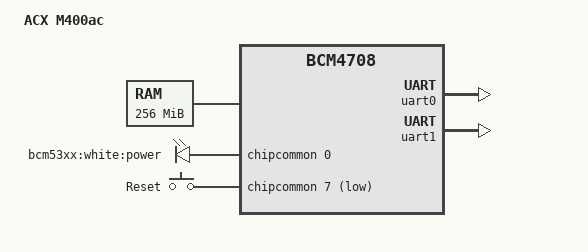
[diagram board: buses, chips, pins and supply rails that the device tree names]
/*
 * Broadcom BCM470X / BCM5301X arm platform code.
 * DTS for SmartRG SR400ac
 *
 * Copyright (C) 2015 Rafał Miłecki <zajec5@gmail.com>
 *
 * Licensed under the GNU/GPL. See COPYING for details.
 */

/dts-v1/;

#include "bcm4708.dtsi"

/ {
	compatible = "acx,m400ac", "brcm,bcm4708";
	model = "ACX M400ac";

	chosen {
		bootargs = "console=ttyS0,115200 earlyprintk";
	};

	memory {
		reg = <0x00000000 0x08000000 0x88000000 0x08000000>;
	};

	chipcommonA {
		uart0: serial@0300 {
			status = "okay";
		};

		uart1: serial@0400 {
			status = "okay";
		};
	};

	leds {
		compatible = "gpio-leds";

		power-white {
			label = "bcm53xx:white:power";
			gpios = <&chipcommon 0 GPIO_ACTIVE_HIGH>;
			linux,default-trigger = "default-on";
		};
	};

	gpio-keys {
		compatible = "gpio-keys";
		#address-cells = <1>;
		#size-cells = <0>;

		restart {
			label = "Reset";
			linux,code = <KEY_RESTART>;
			gpios = <&chipcommon 7 GPIO_ACTIVE_LOW>;
		};
	};
};
